# platform_designer_hps_system_hps_0_hps register map
Vendor: default_vendor.com; File version: 0.0
Registers are 32-bit, read-write, reset 0x0 unless marked. A register's access mark holds for its fields unless they carry their own. Offsets are from the block's base; [hi:lo] are bit positions; lines under a group give offsets from that group.

## emac0 (part 4 of 5) — Registers in the EMAC module.
Base 0xFF700000
Same registers: emac1 0xFF702000
0x474 gmacgrp_Layer3_Addr1_Reg2 — For IPv4 frames, the Layer 3 Address 1 Register 2 contains the 32-bit IP Destination Address field. For IPv6 frames, it contains Bits [63:32] of the 128-bit IP Source Address or Destination Address field.
  [31:0] l3a12 — Layer 3 Address 1 Field When Bit 0 (L3PEN2) and Bit 2 (L3SAM2) are set in Register 280 (Layer 3 and Layer 4 Control Register 2), this field contains the value to be matched with Bits [63:32] of the IP Source Address field in the IPv6 frames. When Bit 0 (L3PEN2) and Bit 4 (L3DAM2) are set in Register 280 (Layer 3 and Layer 4 Control Register 2), this field contains the value to be matched with Bits [63:32] of the IP Destination Address field in the IPv6 frames. When Bit 0 (L3PEN2) is reset and Bit 4 (L3DAM2) is set in Register 280 (Layer 3 and Layer 4 Control Register 2), this field contains the value to be matched with the IP Destination Address field in the IPv4 frames.
0x478 gmacgrp_Layer3_Addr2_Reg2 — For IPv4 frames, the Layer 3 Address 2 Register 2 is reserved. For IPv6 frames, it contains Bits [95:64] of the 128-bit IP Source Address or Destination Address field.
  [31:0] l3a22 — When Bit 0 (L3PEN2) and Bit 2 (L3SAM2) are set in Register 280 (Layer 3 and Layer 4 Control Register 2), this field contains the value to be matched with Bits [95:64] of the IP Source Address field in the IPv6 frames. When Bit 0 (L3PEN2) and Bit 4 (L3DAM2) are set in Register 256 (Layer 3 and Layer 4 Control Register 2), this field contains value to be matched with Bits [95:64] of the IP Destination Address field in the IPv6 frames. When Bit 0 (L3PEN2) is reset in Register 280 (Layer 3 and Layer 4 Control Register 2), this register is not used.
0x47C gmacgrp_Layer3_Addr3_Reg2 — For IPv4 frames, the Layer 3 Address 3 Register 2 is reserved. For IPv6 frames, it contains Bits [127:96] of the 128-bit IP Source Address or Destination Address field.
  [31:0] l3a32 — When Bit 0 (L3PEN2) and Bit 2 (L3SAM2) are set in Register 280 (Layer 3 and Layer 4 Control Register 2), this field contains the value to be matched with Bits [127:96] of the IP Source Address field in the IPv6 frames. When Bit 0 (L3PEN2) and Bit 4 (L3DAM2) are set in Register 280 (Layer 3 and Layer 4 Control Register 2), this field contains the value to be matched with Bits [127:96] of the IP Destination Address field in the IPv6 frames. When Bit 0 (L3PEN2) is reset in Register 280 (Layer 3 and Layer 4 Control Register 2), this register is not used.
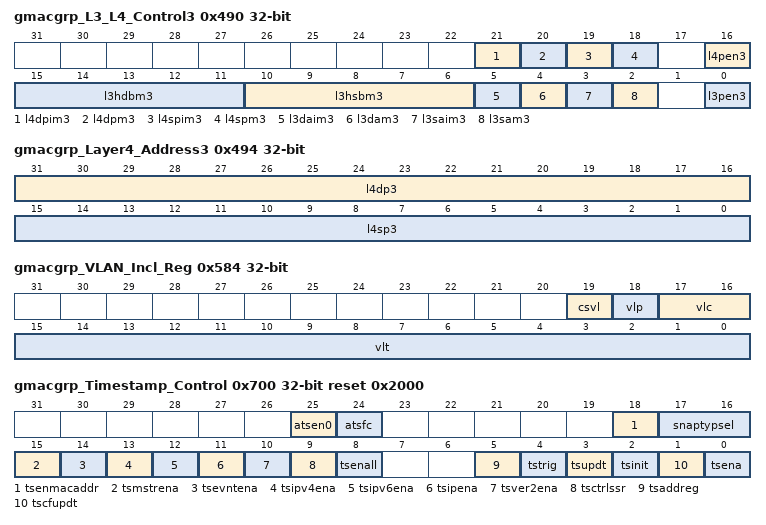
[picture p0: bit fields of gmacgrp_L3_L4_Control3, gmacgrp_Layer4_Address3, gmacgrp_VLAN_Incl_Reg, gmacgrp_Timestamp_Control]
0x490 gmacgrp_L3_L4_Control3 — This register controls the operations of the filter 0 of Layer 3 and Layer 4.
  [21] l4dpim3 — When set, this bit indicates that the Layer 4 Destination Port number field is enabled for inverse matching. When reset, this bit indicates that the Layer 4 Destination Port number field is enabled for perfect matching. This bit is valid and applicable only when Bit 20 (L4DPM3) is set high.
  [20] l4dpm3 — When set, this bit indicates that the Layer 4 Destination Port number field is enabled for matching. When reset, the MAC ignores the Layer 4 Destination Port number field for matching.
  [19] l4spim3 — When set, this bit indicates that the Layer 4 Source Port number field is enabled for inverse matching. When reset, this bit indicates that the Layer 4 Source Port number field is enabled for perfect matching. This bit is valid and applicable only when Bit 18 (L4SPM3) is set high.
  [18] l4spm3 — When set, this bit indicates that the Layer 4 Source Port number field is enabled for matching. When reset, the MAC ignores the Layer 4 Source Port number field for matching.
  [16] l4pen3 — When set, this bit indicates that the Source and Destination Port number fields for UDP frames are used for matching. When reset, this bit indicates that the Source and Destination Port number fields for TCP frames are used for matching. The Layer 4 matching is done only when either L4SPM3 or L4DPM3 bit is set high.
  [15:11] l3hdbm3 — Layer 3 IP DA Higher Bits Match IPv4 Frames: This field contains the number of higher bits of IP Destination Address that are matched in the IPv4 frames. The following list describes the values of this field: * 0: No bits are masked. * 1: LSb[0] is masked. * 2: Two LSbs [1:0] are masked. * ... * 31: All bits except MSb are masked. IPv6 Frames: Bits [12:11] of this field correspond to Bits [6:5] of L3HSBM3, which indicate the number of lower bits of IP Source or Destination Address that are masked in the IPv6 frames. The following list describes the concatenated values of the L3HDBM3[1:0] and L3HSBM3 bits: * 0: No bits are masked. * 1: LSb[0] is masked. * 2: Two LSbs [1:0] are masked. * ... * 127: All bits except MSb are masked. This field is valid and applicable only if L3DAM3 or L3SAM3 is set high.
  [10:6] l3hsbm3 — IPv4 Frames: This field contains the number of lower bits of IP Source Address that are masked for matching in the IPv4 frames. The following list describes the values of this field: * 0: No bits are masked. * 1: LSb[0] is masked. * 2: Two LSbs [1:0] are masked. * ... * 31: All bits except MSb are masked. IPv6 Frames: This field contains Bits [4:0] of the field that indicates the number of higher bits of IP Source or Destination Address matched in the IPv6 frames. This field is valid and applicable only if L3DAM3 or L3SAM3 is set high.
  [5] l3daim3 — When set, this bit indicates that the Layer 3 IP Destination Address field is enabled for inverse matching. When reset, this bit indicates that the Layer 3 IP Destination Address field is enabled for perfect matching. This bit is valid and applicable only when Bit 4 (L3DAM3) is set high.
  [4] l3dam3 — When set, this bit indicates that Layer 3 IP Destination Address field is enabled for matching. When reset, the MAC ignores the Layer 3 IP Destination Address field for matching. Note: When Bit 0 (L3PEN3) is set, you should set either this bit or Bit 2 (L3SAM3) because either IPv6 DA or SA can be checked for filtering.
  [3] l3saim3 — When set, this bit indicates that the Layer 3 IP Source Address field is enabled for inverse matching. When reset, this bit indicates that the Layer 3 IP Source Address field is enabled for perfect matching. This bit is valid and applicable only when Bit 2 (L3SAM3) is set high.
  [2] l3sam3 — When set, this bit indicates that the Layer 3 IP Source Address field is enabled for matching. When reset, the MAC ignores the Layer 3 IP Source Address field for matching. Note: When Bit 0 (L3PEN3) is set, you should set either this bit or Bit 4 (L3DAM3) because either IPv6 SA or DA can be checked for filtering.
  [0] l3pen3 — When set, this bit indicates that the Layer 3 IP Source or Destination Address matching is enabled for the IPv6 frames. When reset, this bit indicates that the Layer 3 IP Source or Destination Address matching is enabled for the IPv4 frames. The Layer 3 matching is done only when either L3SAM3 or L3DAM3 bit is set high.
0x494 gmacgrp_Layer4_Address3 — Because the Layer 3 and Layer 4 Address Registers are double-synchronized to the Rx clock domains, then the synchronization is triggered only when Bits[31:24] (in little-endian mode) or Bits[7:0] (in big-endian mode) of the Layer 3 and Layer 4 Address Registers are written. For proper synchronization updates, you should perform the consecutive writes to the same Layer 3 and Layer 4 Address Registers after at least four clock cycles delay of the destination clock.
  [31:16] l4dp3 — When Bit 16 (L4PEN3) is reset and Bit 20 (L4DPM3) is set in Register 292 (Layer 3 and Layer 4 Control Register 3), this field contains the value to be matched with the TCP Destination Port Number field in the IPv4 or IPv6 frames. When Bit 16 (L4PEN3) and Bit 20 (L4DPM3) are set in Register 292 (Layer 3 and Layer 4 Control Register 3), this field contains the value to be matched with the UDP Destination Port Number field in the IPv4 or IPv6 frames.
  [15:0] l4sp3 — When Bit 16 (L4PEN3) is reset and Bit 20 (L4DPM3) is set in Register 292 (Layer 3 and Layer 4 Control Register 3), this field contains the value to be matched with the TCP Source Port Number field in the IPv4 or IPv6 frames. When Bit 16 (L4PEN3) and Bit 20 (L4DPM3) are set in Register 292 (Layer 3 and Layer 4 Control Register 3), this field contains the value to be matched with the UDP Source Port Number field in the IPv4 or IPv6 frames.
0x4A0 gmacgrp_Layer3_Addr0_Reg3 — For IPv4 frames, the Layer 3 Address 0 Register 3 contains the 32-bit IP Source Address field. For IPv6 frames, it contains Bits [31:0] of the 128-bit IP Source Address or Destination Address field.
  [31:0] l3a03 — When Bit 0 (L3PEN3) and Bit 2 (L3SAM3) are set in Register 292 (Layer 3 and Layer 4 Control Register 3), this field contains the value to be matched with Bits [31:0] of the IP Source Address field in the IPv6 frames. When Bit 0 (L3PEN3) and Bit 4 (L3DAM3) are set in Register 292 (Layer 3 and Layer 4 Control Register 3), this field contains the value to be matched with Bits [31:0] of the IP Destination Address field in the IPv6 frames. When Bit 0 (L3PEN3) is reset and Bit 2 (L3SAM3) is set in Register 292 (Layer 3 and Layer 4 Control Register 3), this field contains the value to be matched with the IP Source Address field in the IPv4 frames.
0x4A4 gmacgrp_Layer3_Addr1_Reg3 — For IPv4 frames, the Layer 3 Address 1 Register 3 contains the 32-bit IP Destination Address field. For IPv6 frames, it contains Bits [63:32] of the 128-bit IP Source Address or Destination Address field.
  [31:0] l3a13 — When Bit 0 (L3PEN3) and Bit 2 (L3SAM3) are set in Register 292 (Layer 3 and Layer 4 Control Register 3), this field contains the value to be matched with Bits [63:32] of the IP Source Address field in the IPv6 frames. When Bit 0 (L3PEN3) and Bit 4 (L3DAM3) are set in Register 292 (Layer 3 and Layer 4 Control Register 3), this field contains the value to be matched with Bits [63:32] of the IP Destination Address field in the IPv6 frames. When Bit 0 (L3PEN3) is reset and Bit 4 (L3DAM3) is set in Register 292 (Layer 3 and Layer 4 Control Register 3), this field contains the value to be matched with the IP Destination Address field in the IPv4 frames.
0x4A8 gmacgrp_Layer3_Addr2_Reg3 — For IPv4 frames, the Layer 3 Address 2 Register 3 is reserved. For IPv6 frames, it contains Bits [95:64] of the 128-bit IP Source Address or Destination Address field.
  [31:0] l3a23 — When Bit 0 (L3PEN3) and Bit 2 (L3SAM3) are set in Register 292 (Layer 3 and Layer 4 Control Register 3), this field contains the value to be matched with Bits [95:64] of the IP Source Address field in the IPv6 frames. When Bit 0 (L3PEN3) and Bit 4 (L3DAM3) are set in Register 292 (Layer 3 and Layer 4 Control Register 3), this field contains value to be matched with Bits [95:64] of the IP Destination Address field in the IPv6 frames. When Bit 0 (L3PEN3) is reset in Register 292 (Layer 3 and Layer 4 Control Register 3), this register is not used.
0x4AC gmacgrp_Layer3_Addr3_Reg3 — For IPv4 frames, the Layer 3 Address 3 Register 3 is reserved. For IPv6 frames, it contains Bits [127:96] of the 128-bit IP Source Address or Destination Address field.
  [31:0] l3a33 — When Bit 0 (L3PEN3) and Bit 2 (L3SAM3) are set in Register 292 (Layer 3 and Layer 4 Control Register 3), this field contains the value to be matched with Bits [127:96] of the IP Source Address field in the IPv6 frames. When Bit 0 (L3PEN3) and Bit 4 (L3DAM3) are set in Register 292 (Layer 3 and Layer 4 Control Register 3), this field contains the value to be matched with Bits [127:96] of the IP Destination Address field in the IPv6 frames. When Bit 0 (L3PEN3) is reset in Register 292 (Layer 3 and Layer 4 Control Register 3), this register is not used.
0x500 gmacgrp_Hash_Table_Reg0 — This register contains the first 32 bits of the hash table. The 256-bit Hash table is used for group address filtering. For hash filtering, the content of the destination address in the incoming frame is passed through the CRC logic and the upper eight bits of the CRC register are used to index the content of the Hash table. The most significant bits determines the register to be used (Hash Table Register X), and the least significant five bits determine the bit within the register. For example, a hash value of 8b'10111111 selects Bit 31 of the Hash Table Register 5. The hash value of the destination address is calculated in the following way: 1. Calculate the 32-bit CRC for the DA (See IEEE 802.3, Section 3.2.8 for the steps to calculate CRC32). 2. Perform bitwise reversal for the value obtained in Step 1. 3. Take the upper 8 bits from the value obtained in Step 2. If the corresponding bit value of the register is 1'b1, the frame is accepted. Otherwise, it is rejected. If the Bit 1 (Pass All Multicast) is set in Register 1 (MAC Frame Filter), then all multicast frames are accepted regardless of the multicast hash values. Because the Hash Table register is double-synchronized to the (G)MII clock domain, the synchronization is triggered only when Bits[31:24] (in little-endian mode) or Bits[7:0] (in big-endian mode) of the Hash Table Register X registers are written. Note: Because of double-synchronization, consecutive writes to this register should be performed after at least four clock cycles in the destination clock domain.
  [31:0] ht31t0 — This field contains the first 32 Bits (31:0) of the Hash table.
0x504 gmacgrp_Hash_Table_Reg1 — This register contains the second 32 bits of the hash table.
  [31:0] ht63t32 — This field contains the second 32 Bits (63:32) of the Hash table.
0x508 gmacgrp_Hash_Table_Reg2 — This register contains the third 32 bits of the hash table.
  [31:0] ht95t64 — This field contains the third 32 Bits (95:64) of the Hash table.
0x50C gmacgrp_Hash_Table_Reg3 — This register contains the fourth 32 bits of the hash table.
  [31:0] ht127t96 — This field contains the fourth 32 Bits (127:96) of the Hash table.
0x510 gmacgrp_Hash_Table_Reg4 — This register contains the fifth 32 bits of the hash table.
  [31:0] ht159t128 — This field contains the fifth 32 Bits (159:128) of the Hash table.
0x514 gmacgrp_Hash_Table_Reg5 — This register contains the sixth 32 bits of the hash table.
  [31:0] ht191t160 — This field contains the sixth 32 Bits (191:160) of the Hash table.
0x518 gmacgrp_Hash_Table_Reg6 — This register contains the seventh 32 bits of the hash table.
  [31:0] ht223t196 — This field contains the seventh 32 Bits (223:196) of the Hash table.
0x51C gmacgrp_Hash_Table_Reg7 — This register contains the eighth 32 bits of the hash table.
  [31:0] ht255t224 — This field contains the eighth 32 Bits (255:224) of the Hash table.
0x584 gmacgrp_VLAN_Incl_Reg (reset mask 0xFFF00000) — The VLAN Tag Inclusion or Replacement register contains the VLAN tag for insertion or replacement in the transmit frames.
  [19] csvl — When this bit is set, S-VLAN type (0x88A8) is inserted or replaced in the 13th and 14th bytes of transmitted frames. When this bit is reset, C-VLAN type (0x8100) is inserted or replaced in the transmitted frames.
  [18] vlp — When this bit is set, the control Bits [17:16] are used for VLAN deletion, insertion, or replacement. When this bit is reset, the mti_vlan_ctrl_i control input is used, and Bits [17:16] are ignored.
  [17:16] vlc — * 2'b00: No VLAN tag deletion, insertion, or replacement * 2'b01: VLAN tag deletion The MAC removes the VLAN type (bytes 13 and 14) and VLAN tag (bytes 15 and 16) of all transmitted frames with VLAN tags. * 2'b10: VLAN tag insertion The MAC inserts VLT in bytes 15 and 16 of the frame after inserting the Type value (0x8100/0x88a8) in bytes 13 and 14. This operation is performed on all transmitted frames, irrespective of whether they already have a VLAN tag. * 2'b11: VLAN tag replacement The MAC replaces VLT in bytes 15 and 16 of all VLAN-type transmitted frames (Bytes 13 and 14 are 0x8100/0x88a8). Note: Changes to this field take effect only on the start of a frame. If you write this register field when a frame is being transmitted, only the subsequent frame can use the updated value, that is, the current frame does not use the updated value.
  [15:0] vlt — This field contains the value of the VLAN tag to be inserted or replaced. The value must only be changed when the transmit lines are inactive or during the initialization phase. Bits[15:13] are the User Priority, Bit 12 is the CFI/DEI, and Bits[11:0] are the VLAN tag's VID field.
0x588 gmacgrp_VLAN_Hash_Table_Reg — The 16-bit Hash table is used for group address filtering based on VLAN tag when Bit 18 (VTHM) of Register 7 (VLAN Tag Register) is set. For hash filtering, the content of the 16-bit VLAN tag or 12-bit VLAN ID (based on Bit 16 (ETV) of VLAN Tag Register) in the incoming frame is passed through the CRC logic and the upper four bits of the calculated CRC are used to index the contents of the VLAN Hash table. For example, a hash value of 4b'1000 selects Bit 8 of the VLAN Hash table. The hash value of the destination address is calculated in the following way: 1. Calculate the 32-bit CRC for the VLAN tag or ID (See IEEE 802.3, Section 3.2.8 for the steps to calculate CRC32). 2. Perform bitwise reversal for the value obtained in Step 1. 3. Take the upper four bits from the value obtained in Step 2. If the corresponding bit value of the register is 1'b1, the frame is accepted. Otherwise, it is rejected. Because the Hash Table register is double-synchronized to the (G)MII clock domain, the synchronization is triggered only when Bits[15:8] (in little-endian mode) or Bits[7:0] (in big-endian mode) of this register are written. Notes: * Because of double-synchronization, consecutive writes to this register should be performed after at least four clock cycles in the destination clock domain.
  [15:0] vlht — This field contains the 16-bit VLAN Hash Table.
0x700 gmacgrp_Timestamp_Control reset 0x2000 — This register controls the operation of the System Time generator and the processing of PTP packets for timestamping in the Receiver.
  [25] atsen0 — This field controls capturing the Auxiliary Snapshot Trigger 0. When this bit is set, the Auxiliary snapshot of event on ptp_aux_trig_i[0] input is enabled. When this bit is reset, the events on this input are ignored.
    0=disabled; 1=enabled
  [24] atsfc — When set, it resets the pointers of the Auxiliary Snapshot FIFO. This bit is cleared when the pointers are reset and the FIFO is empty. When this bit is high, auxiliary snapshots get stored in the FIFO.
    0=disabled; 1=enabled
  [18] tsenmacaddr — When set, the DA MAC address (that matches any MAC Address register) is used to filter the PTP frames when PTP is directly sent over Ethernet.
    0=disabled; 1=enabled
  [17:16] snaptypsel — These bits along with Bits 15 and 14 decide the set of PTP packet types for which snapshot needs to be taken.
  [15] tsmstrena — When set, the snapshot is taken only for the messages relevant to the master node. Otherwise, the snapshot is taken for the messages relevant to the slave node.
    0=slave; 1=master
  [14] tsevntena — When set, the timestamp snapshot is taken only for event messages (SYNC, Delay_Req, Pdelay_Req, or Pdelay_Resp). When reset, the snapshot is taken for all messages except Announce, Management, and Signaling.
    0=disabled; 1=enabled
  [13] tsipv4ena — When set, the MAC receiver processes the PTP packets encapsulated in UDP over IPv4 packets. When this bit is clear, the MAC ignores the PTP transported over UDP-IPv4 packets. This bit is set by default.
    0=no_process_ptp; 1=process_ptp
  [12] tsipv6ena — When set, the MAC receiver processes PTP packets encapsulated in UDP over IPv6 packets. When this bit is clear, the MAC ignores the PTP transported over UDP-IPv6 packets.
    0=no_process_ptp; 1=process_ptp
  [11] tsipena — When set, the MAC receiver processes the PTP packets encapsulated directly in the Ethernet frames. When this bit is clear, the MAC ignores the PTP over Ethernet packets.
    0=no_process_ptp; 1=process_ptp
  [10] tsver2ena — When set, the PTP packets are processed using the 1588 version 2 format. Otherwise, the PTP packets are processed using the version 1 format.
    0=ptp_1588_ver1; 1=ptp_1588_ver2
  [9] tsctrlssr — When set, the Timestamp Low register rolls over after 0x3B9A_C9FF value (that is, 1 nanosecond accuracy) and increments the timestamp (High) seconds. When reset, the rollover value of sub-second register is 0x7FFF_FFFF. The sub-second increment has to be programmed correctly depending on the PTP reference clock frequency and the value of this bit.
    0=notimestamp_low_roll_max; 1=timestamp_low_roll_1ns
  [8] tsenall — When set, the timestamp snapshot is enabled for all frames received by the MAC.
    0=disabled; 1=enabled
  [5] tsaddreg — When set, the content of the Timestamp Addend register is updated in the PTP block for fine correction. This is cleared when the update is completed. This register bit should be zero before setting it.
    0=notimestamp_addend_updated; 1=timestamp_addend_updated
  [4] tstrig — When set, the timestamp interrupt is generated when the System Time becomes greater than the value written in the Target Time register. This bit is reset after the generation of the Timestamp Trigger Interrupt.
    0=notimestamp_intr_trig_en; 1=timestamp_intr_trig_en
  [3] tsupdt — When set, the system time is updated (added or subtracted) with the value specified in Register 452 (System Time - Seconds Update Register) and Register 453 (System Time - Nanoseconds Update Register). This bit should be read zero before updating it. This bit is reset when the update is completed in hardware. The Timestamp Higher Word register is not updated.
    0=notimestamp_updated; 1=timestamp_updated
  [2] tsinit — When set, the system time is initialized (overwritten) with the value specified in the Register 452 (System Time - Seconds Update Register) and Register 453 (System Time - Nanoseconds Update Register). This bit should be read zero before updating it. This bit is reset when the initialization is complete. The Timestamp Higher Word register can only be initialized.
    0=notimestamp_init; 1=timestamp_init
  [1] tscfupdt — When set, this bit indicates that the system times update should be done using the fine update method. When reset, it indicates the system timestamp update should be done using the Coarse method.
    0=timestamp_coarse; 1=timestamp_fine
  [0] tsena — When set, the timestamp is added for the transmit and receive frames. When disabled, timestamp is not added for the transmit and receive frames and the Timestamp Generator is also suspended. You need to initialize the Timestamp (system time) after enabling this mode. On the receive side, the MAC processes the 1588 frames only if this bit is set.
    0=notimestamp; 1=timestamp
0x704 gmacgrp_Sub_Second_Increment — In the Coarse Update mode (TSCFUPDT bit in Register 448), the value in this register is added to the system time every clock cycle of clk_ptp_ref_i. In the Fine Update mode, the value in this register is added to the system time whenever the Accumulator gets an overflow.
  [7:0] ssinc — The value programmed in this field is accumulated every clock cycle (of clk_ptp_i) with the contents of the sub-second register. For example, when PTP clock is 50 MHz (period is 20 ns), you should program 20 (0x14) when the System Time-Nanoseconds register has an accuracy of 1 ns (TSCTRLSSR bit is set). When TSCTRLSSR is clear, the Nanoseconds register has a resolution of ~0.465ns. In this case, you should program a value of 43 (0x2B) that is derived by 20ns/0.465.
0x708 gmacgrp_System_Time_Seconds ro — The System Time -Seconds register, along with System-TimeNanoseconds register, indicates the current value of the system time maintained by the MAC. Though it is updated on a continuous basis, there is some delay from the actual time because of clock domain transfer latencies (from clk_ptp_ref_i to l3_sp_clk).
  [31:0] tss — The value in this field indicates the current value in seconds of the System Time maintained by the MAC.
0x70C gmacgrp_System_Time_Nanoseconds ro — The value in this field has the sub second representation of time, with an accuracy of 0.46 ns. When TSCTRLSSR is set, each bit represents 1 ns and the maximum value is 0x3B9A_C9FF, after which it rolls-over to zero.
  [30:0] tsss — The value in this field has the sub second representation of time, with an accuracy of 0.46 ns. When bit 9 (TSCTRLSSR) is set in Register 448 (Timestamp Control Register), each bit represents 1 ns and the maximum value is 0x3B9A_C9FF, after which it rolls-over to zero.
0x710 gmacgrp_System_Time_Seconds_Update — The System Time - Seconds Update register, along with the System Time - Nanoseconds Update register, initializes or updates the system time maintained by the MAC. You must write both of these registers before setting the TSINIT or TSUPDT bits in the Timestamp Control register.
  [31:0] tss — The value in this field indicates the time in seconds to be initialized or added to the system time.
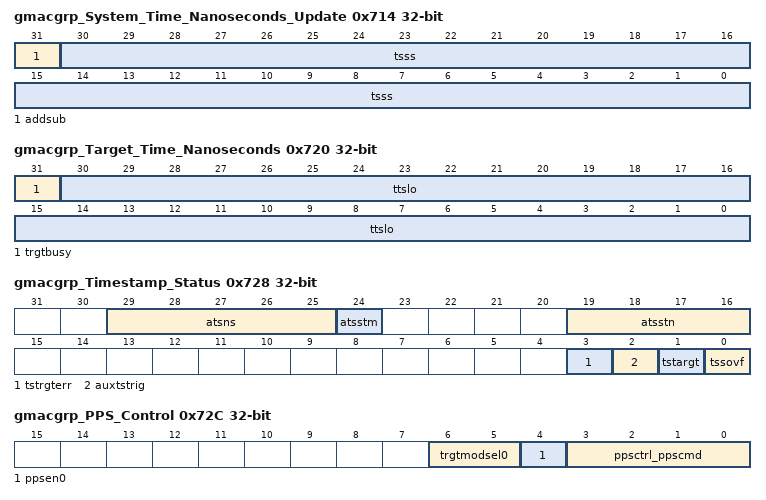
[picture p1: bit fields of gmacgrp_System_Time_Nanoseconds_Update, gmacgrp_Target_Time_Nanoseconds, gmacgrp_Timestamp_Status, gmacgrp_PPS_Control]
0x714 gmacgrp_System_Time_Nanoseconds_Update — Update system time
  [31] addsub — When this bit is set, the time value is subtracted with the contents of the update register. When this bit is reset, the time value is added with the contents of the update register.
    0=disabled; 1=enabled
  [30:0] tsss — The value in this field has the sub second representation of time, with an accuracy of 0.46 ns. When bit 9 (TSCTRLSSR) is set in Register 448 (Timestamp Control Register), each bit represents 1 ns and the programmed value should not exceed 0x3B9A_C9FF.
0x718 gmacgrp_Timestamp_Addend — This register value is used only when the system time is configured for Fine Update mode (TSCFUPDT bit in Register 448). This register content is added to a 32-bit accumulator in every clock cycle (of clk_ptp_ref_i) and the system time is updated whenever the accumulator overflows.
  [31:0] tsar — This field indicates the 32-bit time value to be added to the Accumulator register to achieve time synchronization.
0x71C gmacgrp_Target_Time_Seconds — The Target Time Seconds register, along with Target Time Nanoseconds register, is used to schedule an interrupt event (Register 458[1] when Advanced Timestamping is enabled; otherwise, TS interrupt bit in Register14[9]) when the system time exceeds the value programmed in these registers.
  [31:0] tstr — This register stores the time in seconds. When the timestamp value matches or exceeds both Target Timestamp registers, then based on Bits [6:5] of Register 459 (PPS Control Register), the MAC starts or stops the PPS signal output and generates an interrupt (if enabled).
0x720 gmacgrp_Target_Time_Nanoseconds — Target time
  [31] trgtbusy ro — The MAC sets this bit when the PPSCMD field (Bits[3:0]) in Register 459 (PPS Control Register) is programmed to 010 or 011. Programming the PPSCMD field to 010 or 011, instructs the MAC to synchronize the Target Time Registers to the PTP clock domain. The MAC clears this bit after synchronizing the Target Time Registers to the PTP clock domain The application must not update the Target Time Registers when this bit is read as 1. Otherwise, the synchronization of the previous programmed time gets corrupted. This bit is reserved when the Enable Flexible Pulse-Per-Second Output feature is not selected.
  [30:0] ttslo — This register stores the time in (signed) nanoseconds. When the value of the timestamp matches the both Target Timestamp registers, then based on the TRGTMODSEL0 field (Bits [6:5]) in Register 459 (PPS Control Register), the MAC starts or stops the PPS signal output and generates an interrupt (if enabled). This value should not exceed 0x3B9A_C9FF when TSCTRLSSR is set in the Timestamp control register. The actual start or stop time of the PPS signal output may have an error margin up to one unit of sub-second increment value.
0x724 gmacgrp_System_Time_Higher_Word_Seconds — System time higher word
  [15:0] tshwr — This field contains the most significant 16-bits of the timestamp seconds value. The register is directly written to initialize the value. This register is incremented when there is an overflow from the 32-bits of the System Time - Seconds register.
0x728 gmacgrp_Timestamp_Status ro — Timestamp status. All bits except Bits[27:25] get cleared when the host reads this register.
  [29:25] atsns — This field indicates the number of Snapshots available in the FIFO. A value of 16 (equal to the depth of the FIFO) indicates that the Auxiliary Snapshot FIFO is full. These bits are cleared (to 00000) when the Auxiliary snapshot FIFO clear bit is set.
  [24] atsstm — This bit is set when the Auxiliary timestamp snapshot FIFO is full and external trigger was set. This indicates that the latest snapshot is not stored in the FIFO.
    0=notfull; 1=full
  [19:16] atsstn — These bits identify the Auxiliary trigger inputs for which the timestamp available in the Auxiliary Snapshot Register is applicable. When more than one bit is set at the same time, it means that corresponding auxiliary triggers were sampled at the same clock. These bits are applicable only if the number of Auxiliary snapshots is more than one. One bit is assigned for each trigger as shown in the following list: * Bit 16: Auxiliary trigger 0 * Bit 17: Auxiliary trigger 1 * Bit 18: Auxiliary trigger 2 * Bit 19: Auxiliary trigger 3 The software can read this register to find the triggers that are set when the timestamp is taken.
  [3] tstrgterr — This bit is set when the target time, being programmed in Target Time Registers, is already elapsed. This bit is cleared when read by the application.
    0=reset; 1=set
  [2] auxtstrig — This bit is set high when the auxiliary snapshot is written to the FIFO.
    0=reset; 1=set
  [1] tstargt — When set, this bit indicates that the value of system time is greater or equal to the value specified in the Register 455 (Target Time Seconds Register) and Register 456 (Target Time Nanoseconds Register).
    0=reset; 1=set
  [0] tssovf — When set, this bit indicates that the seconds value of the timestamp (when supporting version 2 format) has overflowed beyond 32'hFFFF_FFFF.
    0=reset; 1=set
0x72C gmacgrp_PPS_Control — Controls timestamp Pulse-Per-Second output
  [6:5] trgtmodsel0 — This field indicates the Target Time registers (register 455 and 456) mode for PPS0 output signal
    0=trgtinteronly; 2=trgtintpps0; 3=trgtnointer
  [4] ppsen0 — When set low, Bits[3:0] function as PPSCTRL (backward compatible). When set high, Bits[3:0] function as PPSCMD.
    0=ppsctrl; 1=ppscmd
  [3:0] ppsctrl_ppscmd — PPSCTRL0: PPS0 Output Frequency Control This field controls the frequency of the PPS0 output (ptp_pps_o[0]) signal. The default value of PPSCTRL is 0000, and the PPS output is 1 pulse (of width clk_ptp_i) every second. For other values of PPSCTRL, the PPS output becomes a generated clock of following frequencies: -0001: The binary rollover is 2 Hz, and the digital rollover is 1 Hz. -0010: The binary rollover is 4 Hz, and the digital rollover is 2 Hz. -0011: The binary rollover is 8 Hz, and the digital rollover is 4 Hz. -0100: The binary rollover is 16 Hz, and the digital rollover is 8 Hz. -... -1111: The binary rollover is 32.768 KHz, and the digital rollover is 16.384 KHz. Note: In the binary rollover mode, the PPS output (ptp_pps_o) has a duty cycle of 50 percent with these frequencies. In the digital rollover mode, the PPS output frequency is an average number. The actual clock is of different frequency that gets synchronized every second. For example: * When PPSCTRL = 0001, the PPS (1 Hz) has a low period of 537 ms and a high period of 463 ms * When PPSCTRL = 0010, the PPS (2 Hz) is a sequence of: - One clock of 50 percent duty cycle and 537 ms period - Second clock of 463 ms period (268 ms low and 195 ms high) * When PPSCTRL = 0011, the PPS (4 Hz) is a sequence of: - Three clocks of 50 percent duty cycle and 268 ms period - Fourth clock of 195 ms period (134 ms low and 61 ms high) This behavior is because of the non-linear toggling of bits in the digital rollover mode in Register 451 (System Time - Nanoseconds Register). Flexible PPS0 Output (ptp_pps_o[0]) Control Programming these bits with a non-zero value instructs the MAC to initiate an event. Once the command is transferred or synchronized to the PTP clock domain, these bits get cleared automatically. The Software should ensure that these bits are programmed only when they are all-zero. The following list describes the values of PPSCMD0: * 0000: No Command * 0001: START Single Pulse This command generates single pulse rising at the start point defined in Target Time Registers (register 455 and 456) and of a duration defined in the PPS0 Width Register. * 0010: START Pulse Train This command generates the train of pulses rising at the start point defined in the Target Time Registers and of a duration defined in the PPS0 Width Register and repeated at interval defined in the PPS Interval Register. By default, the PPS pulse train is free-running unless stopped by 'STOP Pulse train at time' or 'STOP Pulse Train immediately' commands. * 0011: Cancel START This command cancels the START Single Pulse and START Pulse Train commands if the system time has not crossed the programmed start time. * 0100: STOP Pulse train at time This command stops the train of pulses initiated by the START Pulse Train command (PPSCMD = 0010) after the time programmed in the Target Time registers elapses. * 0101: STOP Pulse Train immediately This command immediately stops the train of pulses initiated by the START Pulse Train command (PPSCMD = 0010). * 0110: Cancel STOP Pulse train This command cancels the STOP pulse train at time command if the programmed stop time has not elapsed. The PPS pulse train becomes free-running on the successful execution of this command. * 0111-1111: Reserved
0x730 gmacgrp_Auxiliary_Timestamp_Nanoseconds ro — This register, along with Register 461 (Auxiliary Timestamp Seconds Register), gives the 64-bit timestamp stored as auxiliary snapshot. The two registers together form the read port of a 64-bit wide FIFO with a depth of 16. Multiple snapshots can be stored in this FIFO. The ATSNS bits in the Timestamp Status register indicate the fill-level of this FIFO. The top of the FIFO is removed only when the last byte of Register 461 (Auxiliary Timestamp - Seconds Register) is read. In the little-endian mode, this means when Bits[31:24] are read. In big-endian mode, it corresponds to the reading of Bits[7:0] of Register 461 (Auxiliary Timestamp - Seconds Register).
  [30:0] auxtslo — Contains the lower 32 bits (nano-seconds field) of the auxiliary timestamp.
0x734 gmacgrp_Auxiliary_Timestamp_Seconds ro — Contains the higher 32 bits (Seconds field) of the auxiliary timestamp.
  [31:0] auxtshi
0x760 gmacgrp_PPS0_Interval — The PPS0 Interval register contains the number of units of sub-second increment value between the rising edges of PPS0 signal output (ptp_pps_o[0]).
  [31:0] ppsint — These bits store the interval between the rising edges of PPS0 signal output in terms of units of sub-second increment value. You need to program one value less than the required interval. For example, if the PTP reference clock is 50 MHz (period of 20ns), and desired interval between rising edges of PPS0 signal output is 100ns (that is, five units of sub-second increment value), then you should program value 4 (5 -1) in this register.
0x764 gmacgrp_PPS0_Width — The PPS0 Width register contains the number of units of sub-second increment value between the rising and corresponding falling edges of the PPS0 signal output (ptp_pps_o[0]).
  [31:0] ppswidth — These bits store the width between the rising edge and corresponding falling edge of the PPS0 signal output in terms of units of sub-second increment value. You need to program one value less than the required interval. For example, if PTP reference clock is 50 MHz (period of 20ns), and desired width between the rising and corresponding falling edges of PPS0 signal output is 80ns (that is, four units of sub-second increment value), then you should program value 3 (4-1) in this register. Note: The value programmed in this register must be lesser than the value programmed in Register 472 (PPS0 Interval Register).
